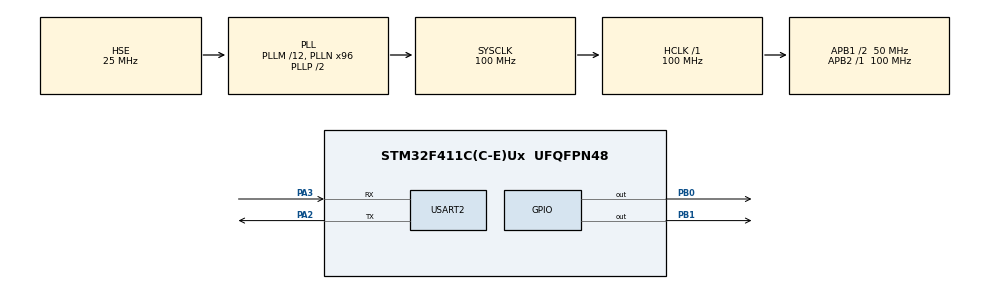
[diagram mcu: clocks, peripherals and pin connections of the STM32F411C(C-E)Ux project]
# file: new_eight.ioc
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FREERTOS.Tasks01=Task_1,24,128,StartTask_1,Default,NULL,Dynamic,NULL,NULL;Task_2,24,128,StartTask_2,Default,NULL,Static,Task_2Buffer,Task_2ControlBlock
Mcu.Family=STM32F4
Mcu.Name=STM32F411C(C-E)Ux
Mcu.Package=UFQFPN48
NVIC.PriorityGroup=NVIC_PRIORITYGROUP_4
NVIC.TIM5_IRQn=true\:15\:0\:false\:false\:true\:false\:false\:true\:true
NVIC.TimeBase=TIM5_IRQn
NVIC.TimeBaseIP=TIM5
PA13.Mode=Serial_Wire
PA13.Signal=SYS_JTMS-SWDIO
PA14.Mode=Serial_Wire
PA14.Signal=SYS_JTCK-SWCLK
PA2.Mode=Asynchronous
PA2.Signal=USART2_TX
PA3.Mode=Asynchronous
PA3.Signal=USART2_RX
PB0.GPIO_PuPd=GPIO_PULLUP
PB0.GPIO_Speed=GPIO_SPEED_FREQ_VERY_HIGH
PB0.Signal=GPIO_Output
PB1.GPIO_PuPd=GPIO_PULLUP
PB1.GPIO_Speed=GPIO_SPEED_FREQ_VERY_HIGH
PB1.Signal=GPIO_Output
PH0\ -\ OSC_IN.Mode=HSE-External-Oscillator
PH0\ -\ OSC_IN.Signal=RCC_OSC_IN
PH1\ -\ OSC_OUT.Mode=HSE-External-Oscillator
PH1\ -\ OSC_OUT.Signal=RCC_OSC_OUT
ProjectManager.HeapSize=0x200
ProjectManager.StackSize=0x400
ProjectManager.TargetToolchain=STM32CubeIDE
RCC.48MHZClocksFreq_Value=50000000
RCC.AHBFreq_Value=100000000
RCC.APB1CLKDivider=RCC_HCLK_DIV2
RCC.APB1Freq_Value=50000000
RCC.APB1TimFreq_Value=100000000
RCC.APB2Freq_Value=100000000
RCC.APB2TimFreq_Value=100000000
RCC.CortexFreq_Value=100000000
RCC.HCLKFreq_Value=100000000
RCC.HSE_VALUE=25000000
RCC.HSI_VALUE=16000000
RCC.LSE_VALUE=32768
RCC.PLLM=12
RCC.PLLN=96
RCC.PLLSourceVirtual=RCC_PLLSOURCE_HSE
RCC.SYSCLKFreq_VALUE=100000000
RCC.SYSCLKSource=RCC_SYSCLKSOURCE_PLLCLK
RCC.VCOOutputFreq_Value=200000000
USART2.VirtualMode=VM_ASYNC
VP_FREERTOS_VS_CMSIS_V2.Mode=CMSIS_V2
VP_SYS_VS_tim5.Mode=TIM5
board=custom

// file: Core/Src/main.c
/* USER CODE BEGIN Header */
/**
  ******************************************************************************
  * @file           : main.c
  * @brief          : Main program body
  ******************************************************************************
  * @attention
  *
  * Copyright (c) 2024 STMicroelectronics.
  * All rights reserved.
  *
  * This software is licensed under terms that can be found in the LICENSE file
  * in the root directory of this software component.
  * If no LICENSE file comes with this software, it is provided AS-IS.
  *
  ******************************************************************************
  */
/* USER CODE END Header */
#include "main.h"
#include "cmsis_os.h"
#include "usart.h"
#include "gpio.h"

void SystemClock_Config(void);
void MX_FREERTOS_Init(void);

int main(void)
{

  /* MCU Configuration--------------------------------------------------------*/

  /* Reset of all peripherals, Initializes the Flash interface and the Systick. */
  HAL_Init();

  /* Configure the system clock */
  SystemClock_Config();

  /* Initialize all configured peripherals */
  MX_GPIO_Init();
  MX_USART2_UART_Init();

  /* Init scheduler */
  osKernelInitialize();

  /* Call init function for freertos objects (in cmsis_os2.c) */
  MX_FREERTOS_Init();

  /* Start scheduler */
  osKernelStart();

  /* We should never get here as control is now taken by the scheduler */

  /* Infinite loop */
  while (1)
  {

  }
}

void SystemClock_Config(void)
{
  RCC_OscInitTypeDef RCC_OscInitStruct = {0};
  RCC_ClkInitTypeDef RCC_ClkInitStruct = {0};

  /** Configure the main internal regulator output voltage
  */
  __HAL_RCC_PWR_CLK_ENABLE();
  __HAL_PWR_VOLTAGESCALING_CONFIG(PWR_REGULATOR_VOLTAGE_SCALE1);

  /** Initializes the RCC Oscillators according to the specified parameters
  * in the RCC_OscInitTypeDef structure.
  */
  RCC_OscInitStruct.OscillatorType = RCC_OSCILLATORTYPE_HSE;
  RCC_OscInitStruct.HSEState = RCC_HSE_ON;
  RCC_OscInitStruct.PLL.PLLState = RCC_PLL_ON;
  RCC_OscInitStruct.PLL.PLLSource = RCC_PLLSOURCE_HSE;
  RCC_OscInitStruct.PLL.PLLM = 12;
  RCC_OscInitStruct.PLL.PLLN = 96;
  RCC_OscInitStruct.PLL.PLLP = RCC_PLLP_DIV2;
  RCC_OscInitStruct.PLL.PLLQ = 4;
  if (HAL_RCC_OscConfig(&RCC_OscInitStruct) != HAL_OK)
  {
    Error_Handler();
  }

  /** Initializes the CPU, AHB and APB buses clocks
  */
  RCC_ClkInitStruct.ClockType = RCC_CLOCKTYPE_HCLK|RCC_CLOCKTYPE_SYSCLK
                              |RCC_CLOCKTYPE_PCLK1|RCC_CLOCKTYPE_PCLK2;
  RCC_ClkInitStruct.SYSCLKSource = RCC_SYSCLKSOURCE_PLLCLK;
  RCC_ClkInitStruct.AHBCLKDivider = RCC_SYSCLK_DIV1;
  RCC_ClkInitStruct.APB1CLKDivider = RCC_HCLK_DIV2;
  RCC_ClkInitStruct.APB2CLKDivider = RCC_HCLK_DIV1;

  if (HAL_RCC_ClockConfig(&RCC_ClkInitStruct, FLASH_LATENCY_3) != HAL_OK)
  {
    Error_Handler();
  }
}

void HAL_TIM_PeriodElapsedCallback(TIM_HandleTypeDef *htim)
{
  if (htim->Instance == TIM5) {
    HAL_IncTick();
  }
}

void Error_Handler(void)
{
  __disable_irq();
  while (1)
  {
  }
}

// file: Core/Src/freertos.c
/* USER CODE BEGIN Header */
/**
  ******************************************************************************
  * File Name          : freertos.c
  * Description        : Code for freertos applications
  ******************************************************************************
  * @attention
  *
  * Copyright (c) 2024 STMicroelectronics.
  * All rights reserved.
  *
  * This software is licensed under terms that can be found in the LICENSE file
  * in the root directory of this software component.
  * If no LICENSE file comes with this software, it is provided AS-IS.
  *
  ******************************************************************************
  */
/* USER CODE END Header */

#include "FreeRTOS.h"
#include "task.h"
#include "main.h"
#include "cmsis_os.h"

typedef StaticTask_t osStaticThreadDef_t;

/* Definitions for Task_1 */
osThreadId_t Task_1Handle;
const osThreadAttr_t Task_1_attributes = {
  .name = "Task_1",
  .stack_size = 128 * 4,
  .priority = (osPriority_t) osPriorityNormal,
};
/* Definitions for Task_2 */
osThreadId_t Task_2Handle;
uint32_t Task_2Buffer[ 128 ];
osStaticThreadDef_t Task_2ControlBlock;
const osThreadAttr_t Task_2_attributes = {
  .name = "Task_2",
  .cb_mem = &Task_2ControlBlock,
  .cb_size = sizeof(Task_2ControlBlock),
  .stack_mem = &Task_2Buffer[0],
  .stack_size = sizeof(Task_2Buffer),
  .priority = (osPriority_t) osPriorityNormal,
};

void StartTask_1(void *argument);
void StartTask_2(void *argument);

void MX_FREERTOS_Init(void); /* (MISRA C 2004 rule 8.1) */

void MX_FREERTOS_Init(void) {

  /* Create the thread(s) */
  /* creation of Task_1 */
  Task_1Handle = osThreadNew(StartTask_1, NULL, &Task_1_attributes);

  /* creation of Task_2 */
  Task_2Handle = osThreadNew(StartTask_2, NULL, &Task_2_attributes);

}

void StartTask_1(void *argument)
{
  /* USER CODE BEGIN StartTask_1 */
  /* Infinite loop */
  for(;;)
  {
    HAL_GPIO_TogglePin(GPIOB, GPIO_PIN_0);
    HAL_Delay(1000);
  }
  /* USER CODE END StartTask_1 */
}

void StartTask_2(void *argument)
{
  /* USER CODE BEGIN StartTask_2 */
  /* Infinite loop */
  for(;;)
  {
	  HAL_GPIO_TogglePin(GPIOB, GPIO_PIN_1);
	  HAL_Delay(1000);
  }
  /* USER CODE END StartTask_2 */
}
